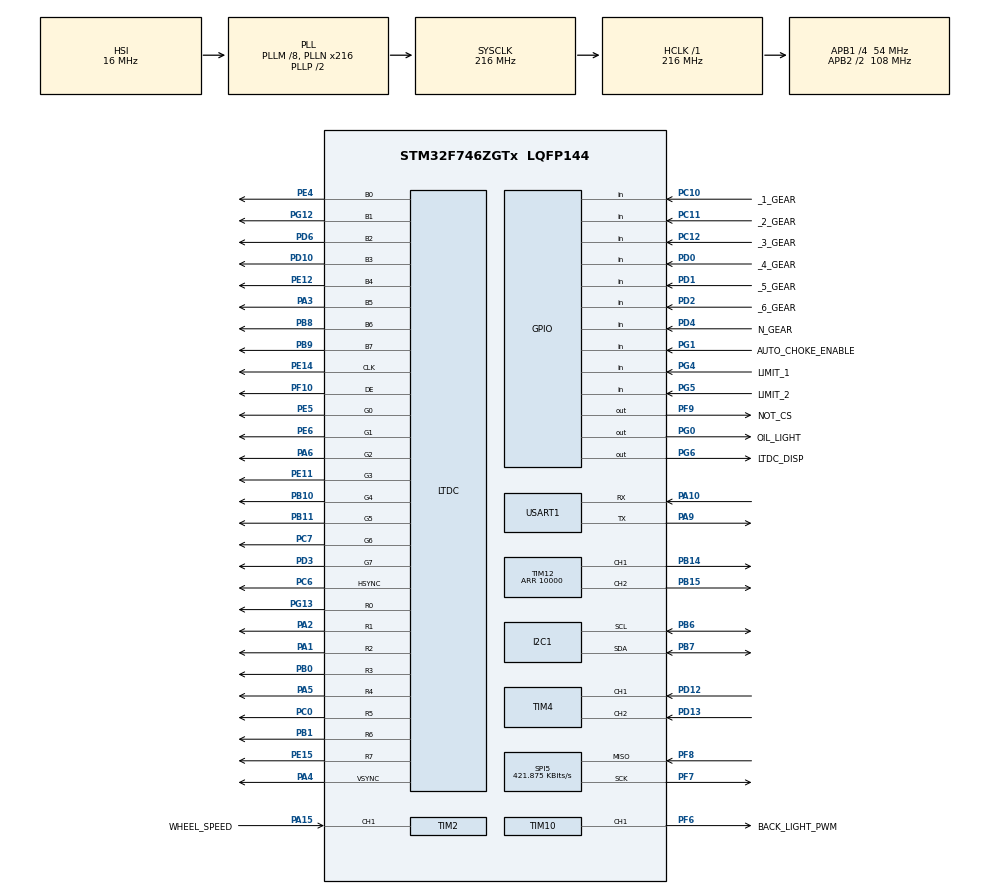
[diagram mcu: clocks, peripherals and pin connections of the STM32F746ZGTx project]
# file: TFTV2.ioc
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CORTEX_M7.ART_ACCELERATOR_ENABLE=1
CORTEX_M7.default_mode_Activation=1
DMA2D.InputColorModeForeground=DMA2D_INPUT_L8
DMA2D.Mode=DMA2D_M2M_PFC
I2C1.Timing=0x20404768
LTDC.ActiveW=800
LTDC.Alpha_L0=255
LTDC.FBStartAdress_L0=0x20000000
LTDC.HBP=8
LTDC.HFP=8
LTDC.HSync=4
LTDC.ImageHeight_L0=380
LTDC.ImageWidth_L0=600
LTDC.Layers=0
LTDC.PixelFormat_L0=LTDC_PIXEL_FORMAT_L8
LTDC.VBP=8
LTDC.VFP=8
LTDC.WindowX0_L0=100
LTDC.WindowX1_L0=700
LTDC.WindowY0_L0=50
LTDC.WindowY1_L0=380+50
Mcu.Family=STM32F7
Mcu.Name=STM32F746ZGTx
Mcu.Package=LQFP144
NVIC.DMA2D_IRQn=true\:0\:0\:false\:false\:true\:true\:true\:true
NVIC.LTDC_IRQn=true\:0\:0\:false\:false\:true\:true\:true\:true
NVIC.PriorityGroup=NVIC_PRIORITYGROUP_4
NVIC.RCC_IRQn=true\:0\:0\:false\:false\:true\:true\:false\:true
NVIC.TIM6_DAC_IRQn=true\:15\:0\:true\:false\:true\:false\:true\:true
NVIC.TimeBase=TIM6_DAC_IRQn
NVIC.TimeBaseIP=TIM6
NVIC.USART1_IRQn=true\:0\:0\:false\:false\:true\:true\:true\:true
PA1.Mode=RGB888
PA1.Signal=LTDC_R2
PA10.Mode=Asynchronous
PA10.Signal=USART1_RX
PA13.Mode=Trace_Asynchronous_SW
PA13.Signal=SYS_JTMS-SWDIO
PA14.Mode=Trace_Asynchronous_SW
PA14.Signal=SYS_JTCK-SWCLK
PA15.GPIO_Label=WHEEL_SPEED
PA15.Signal=S_TIM2_CH1_ETR
PA2.Mode=RGB888
PA2.Signal=LTDC_R1
PA3.Mode=RGB888
PA3.Signal=LTDC_B5
PA4.Mode=RGB888
PA4.Signal=LTDC_VSYNC
PA5.Mode=RGB888
PA5.Signal=LTDC_R4
PA6.Mode=RGB888
PA6.Signal=LTDC_G2
PA9.Mode=Asynchronous
PA9.Signal=USART1_TX
PB0.Mode=RGB888
PB0.Signal=LTDC_R3
PB1.Mode=RGB888
PB1.Signal=LTDC_R6
PB10.Mode=RGB888
PB10.Signal=LTDC_G4
PB11.Mode=RGB888
PB11.Signal=LTDC_G5
PB14.Signal=S_TIM12_CH1
PB15.Signal=S_TIM12_CH2
PB3.Mode=Trace_Asynchronous_SW
PB3.Signal=SYS_JTDO-SWO
PB6.Mode=I2C
PB6.Signal=I2C1_SCL
PB7.Mode=I2C
PB7.Signal=I2C1_SDA
PB8.Mode=RGB888
PB8.Signal=LTDC_B6
PB9.Mode=RGB888
PB9.Signal=LTDC_B7
PC0.Mode=RGB888
PC0.Signal=LTDC_R5
PC10.GPIO_Label=_1_GEAR
PC10.GPIO_PuPd=GPIO_PULLUP
PC10.Signal=GPIO_Input
PC11.GPIO_Label=_2_GEAR
PC11.GPIO_PuPd=GPIO_PULLUP
PC11.Signal=GPIO_Input
PC12.GPIO_Label=_3_GEAR
PC12.GPIO_PuPd=GPIO_PULLUP
PC12.Signal=GPIO_Input
PC6.Mode=RGB888
PC6.Signal=LTDC_HSYNC
PC7.Mode=RGB888
PC7.Signal=LTDC_G6
PD0.GPIO_Label=_4_GEAR
PD0.GPIO_PuPd=GPIO_PULLUP
PD0.Signal=GPIO_Input
PD1.GPIO_Label=_5_GEAR
PD1.GPIO_PuPd=GPIO_PULLUP
PD1.Signal=GPIO_Input
PD10.Mode=RGB888
PD10.Signal=LTDC_B3
PD12.Signal=S_TIM4_CH1
PD13.Signal=S_TIM4_CH2
PD2.GPIO_Label=_6_GEAR
PD2.GPIO_PuPd=GPIO_PULLUP
PD2.Signal=GPIO_Input
PD3.Mode=RGB888
PD3.Signal=LTDC_G7
PD4.GPIO_Label=N_GEAR
PD4.GPIO_PuPd=GPIO_PULLUP
PD4.Signal=GPIO_Input
PD6.Mode=RGB888
PD6.Signal=LTDC_B2
PE11.Mode=RGB888
PE11.Signal=LTDC_G3
PE12.Mode=RGB888
PE12.Signal=LTDC_B4
PE14.Mode=RGB888
PE14.Signal=LTDC_CLK
PE15.Mode=RGB888
PE15.Signal=LTDC_R7
PE4.Mode=RGB888
PE4.Signal=LTDC_B0
PE5.Mode=RGB888
PE5.Signal=LTDC_G0
PE6.Mode=RGB888
PE6.Signal=LTDC_G1
PF10.Mode=RGB888
PF10.Signal=LTDC_DE
PF6.GPIO_Label=BACK_LIGHT_PWM
PF6.Signal=S_TIM10_CH1
PF7.Mode=RX_Only_Simplex_Unidirect_Master
PF7.Signal=SPI5_SCK
PF8.Mode=RX_Only_Simplex_Unidirect_Master
PF8.Signal=SPI5_MISO
PF9.GPIO_Label=NOT_CS
PF9.Signal=GPIO_Output
PG0.GPIO_Label=OIL_LIGHT
PG0.GPIO_PuPd=GPIO_PULLDOWN
PG0.GPIO_Speed=GPIO_SPEED_FREQ_LOW
PG0.PinState=GPIO_PIN_RESET
PG0.Signal=GPIO_Output
PG1.GPIO_Label=AUTO_CHOKE_ENABLE
PG1.GPIO_PuPd=GPIO_PULLDOWN
PG1.Signal=GPIO_Input
PG12.Mode=RGB888
PG12.Signal=LTDC_B1
PG13.Mode=RGB888
PG13.Signal=LTDC_R0
PG4.GPIO_Label=LIMIT_1
PG4.GPIO_PuPd=GPIO_PULLUP
PG4.Signal=GPIO_Input
PG5.GPIO_Label=LIMIT_2
PG5.GPIO_PuPd=GPIO_PULLUP
PG5.Signal=GPIO_Input
PG6.GPIO_Label=LTDC_DISP
PG6.GPIO_PuPd=GPIO_PULLUP
PG6.PinState=GPIO_PIN_SET
PG6.Signal=GPIO_Output
PH0/OSC_IN.Mode=HSE-External-Oscillator
PH0/OSC_IN.Signal=RCC_OSC_IN
PH1/OSC_OUT.Mode=HSE-External-Oscillator
PH1/OSC_OUT.Signal=RCC_OSC_OUT
ProjectManager.HeapSize=0x200
ProjectManager.StackSize=0x400
ProjectManager.TargetToolchain=STM32CubeIDE
RCC.AHBFreq_Value=216000000
RCC.APB1CLKDivider=RCC_HCLK_DIV4
RCC.APB1Freq_Value=54000000
RCC.APB1TimFreq_Value=108000000
RCC.APB2CLKDivider=RCC_HCLK_DIV2
RCC.APB2Freq_Value=108000000
RCC.APB2TimFreq_Value=216000000
RCC.CortexFreq_Value=216000000
RCC.HCLKFreq_Value=216000000
RCC.HSE_VALUE=25000000
RCC.HSI_VALUE=16000000
RCC.LSE_VALUE=32768
RCC.PLLM=8
RCC.PLLN=216
RCC.PLLSAIN=50
RCC.SYSCLKFreq_VALUE=216000000
RCC.SYSCLKSource=RCC_SYSCLKSOURCE_PLLCLK
RCC.USBFreq_Value=216000000
RCC.VCOOutputFreq_Value=432000000
SH.S_TIM10_CH1.0=TIM10_CH1,PWM Generation1 CH1
SH.S_TIM12_CH1.0=TIM12_CH1,PWM Generation1 CH1
SH.S_TIM12_CH2.0=TIM12_CH2,PWM Generation2 CH2
SH.S_TIM2_CH1_ETR.0=TIM2_CH1,TriggerSource_TI1FP1
SH.S_TIM4_CH1.0=TIM4_CH1,Encoder_Interface
SH.S_TIM4_CH2.0=TIM4_CH2,Encoder_Interface
SPI5.BaudRatePrescaler=SPI_BAUDRATEPRESCALER_256
SPI5.CalculateBaudRate=421.875 KBits/s
SPI5.DataSize=SPI_DATASIZE_16BIT
SPI5.Direction=SPI_DIRECTION_2LINES_RXONLY
SPI5.Mode=SPI_MODE_MASTER
SPI5.VirtualType=VM_MASTER
STMicroelectronics.X-CUBE-TOUCHGFX.4.25.0.ApplicationCcGraphicsJjApplication=TouchGFXOoGenerator
STMicroelectronics.X-CUBE-TOUCHGFX.4.25.0.tgfx_display_interface=disp_ltdc
STMicroelectronics.X-CUBE-TOUCHGFX.4.25.0.tgfx_hardware_accelerator=dma_2d
STMicroelectronics.X-CUBE-TOUCHGFX.4.25.0.tgfx_pixel_format=RGBA2222\:8
STMicroelectronics.X-CUBE-TOUCHGFX.4.25.0.tgfx_vsync=vsync_ltdc
STMicroelectronics.X-CUBE-TOUCHGFX.4.25.0_IsPackSelfContextualization=true
TIM10.Channel=TIM_CHANNEL_1
TIM10.Period=2159
TIM12.Channel-PWM\ Generation1\ CH1=TIM_CHANNEL_1
TIM12.Channel-PWM\ Generation2\ CH2=TIM_CHANNEL_2
TIM12.Period=10000
TIM4.EncoderMode=TIM_ENCODERMODE_TI12
USART1.VirtualMode-Asynchronous=VM_ASYNC
VP_CRC_VS_CRC.Mode=CRC_Activate
VP_DMA2D_VS_DMA2D.Mode=DMA2D_Activate
VP_STMicroelectronics.X-CUBE-TOUCHGFX_VS_GraphicsJjApplication_4.25.0.Mode=GraphicsJjApplication
VP_SYS_VS_tim6.Mode=TIM6
VP_TIM10_VS_ClockSourceINT.Mode=Enable_Timer
VP_TIM2_VS_ControllerModeClock.Mode=Clock Mode
board=custom

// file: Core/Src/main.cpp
/* USER CODE BEGIN Header */
/**
  ******************************************************************************
  * @file           : main.cpp
  * @brief          : Main program body for GS425-Dashboard that runs tasks
                      containing FSMs.
  ******************************************************************************
  * @attention
  *
  * Copyright (c) 2025 STMicroelectronics.
  * All rights reserved.
  *
  * This software is licensed under terms that can be found in the LICENSE file
  * in the root directory of this software component.
  * If no LICENSE file comes with this software, it is provided AS-IS.
  *
  ******************************************************************************
  */
/* USER CODE END Header */
#include "main.h"

/* USER CODE BEGIN Includes */
#include <stdio.h>
#include <string.h>
#include <stdbool.h>
#include "task1.h"
#include "task2.h"
#include "app_touchgfx.h"

  TASK1 task1;   // init task 1
  TASK2 task2;   // init task 2

/* USER CODE END Includes */

CRC_HandleTypeDef hcrc;

DMA2D_HandleTypeDef hdma2d;

I2C_HandleTypeDef hi2c1;

LTDC_HandleTypeDef hltdc;

SPI_HandleTypeDef hspi5;

TIM_HandleTypeDef htim2;
TIM_HandleTypeDef htim4;
TIM_HandleTypeDef htim10;
TIM_HandleTypeDef htim12;

UART_HandleTypeDef huart1;

void SystemClock_Config(void);
static void MPU_Config(void);
static void MX_GPIO_Init(void);
static void MX_DMA2D_Init(void);
static void MX_I2C1_Init(void);
static void MX_LTDC_Init(void);
static void MX_USART1_UART_Init(void);
static void MX_CRC_Init(void);
static void MX_TIM10_Init(void);
static void MX_TIM2_Init(void);
static void MX_SPI5_Init(void);
static void MX_TIM4_Init(void);
static void MX_TIM12_Init(void);

int main(void)
{

  /* MPU Configuration--------------------------------------------------------*/
  MPU_Config();

  /* MCU Configuration--------------------------------------------------------*/

  /* Reset of all peripherals, Initializes the Flash interface and the Systick. */
  HAL_Init();

  /* Configure the system clock */
  SystemClock_Config();

  /* Initialize all configured peripherals */
  MX_GPIO_Init();
  MX_DMA2D_Init();
  MX_I2C1_Init();
  MX_LTDC_Init();
  MX_USART1_UART_Init();
  MX_CRC_Init();
  MX_TIM10_Init();
  MX_TIM2_Init();
  MX_SPI5_Init();
  MX_TIM4_Init();
  MX_TIM12_Init();
  MX_TouchGFX_Init();
  /* USER CODE BEGIN 2 */

	//Set up BackLight PWM Channel
	__HAL_TIM_SET_COMPARE(&htim10, TIM_CHANNEL_1, 500);
	HAL_TIM_PWM_Start(&htim10, TIM_CHANNEL_1);

  /* USER CODE END 2 */

  /* Infinite loop */
  /* USER CODE BEGIN WHILE */
  while (1)
  {
	  task1.run();            // task 1
	  task2.run();            // task 2
      MX_TouchGFX_Process();  // task 3

    /* USER CODE END WHILE */

  }
}

void SystemClock_Config(void)
{
  RCC_OscInitTypeDef RCC_OscInitStruct = {0};
  RCC_ClkInitTypeDef RCC_ClkInitStruct = {0};

  /** Configure the main internal regulator output voltage
  */
  __HAL_RCC_PWR_CLK_ENABLE();
  __HAL_PWR_VOLTAGESCALING_CONFIG(PWR_REGULATOR_VOLTAGE_SCALE1);

  /** Initializes the RCC Oscillators according to the specified parameters
  * in the RCC_OscInitTypeDef structure.
  */
  RCC_OscInitStruct.OscillatorType = RCC_OSCILLATORTYPE_HSI;
  RCC_OscInitStruct.HSIState = RCC_HSI_ON;
  RCC_OscInitStruct.HSICalibrationValue = RCC_HSICALIBRATION_DEFAULT;
  RCC_OscInitStruct.PLL.PLLState = RCC_PLL_ON;
  RCC_OscInitStruct.PLL.PLLSource = RCC_PLLSOURCE_HSI;
  RCC_OscInitStruct.PLL.PLLM = 8;
  RCC_OscInitStruct.PLL.PLLN = 216;
  RCC_OscInitStruct.PLL.PLLP = RCC_PLLP_DIV2;
  RCC_OscInitStruct.PLL.PLLQ = 2;
  if (HAL_RCC_OscConfig(&RCC_OscInitStruct) != HAL_OK)
  {
    Error_Handler();
  }

  /** Activate the Over-Drive mode
  */
  if (HAL_PWREx_EnableOverDrive() != HAL_OK)
  {
    Error_Handler();
  }

  /** Initializes the CPU, AHB and APB buses clocks
  */
  RCC_ClkInitStruct.ClockType = RCC_CLOCKTYPE_HCLK|RCC_CLOCKTYPE_SYSCLK
                              |RCC_CLOCKTYPE_PCLK1|RCC_CLOCKTYPE_PCLK2;
  RCC_ClkInitStruct.SYSCLKSource = RCC_SYSCLKSOURCE_PLLCLK;
  RCC_ClkInitStruct.AHBCLKDivider = RCC_SYSCLK_DIV1;
  RCC_ClkInitStruct.APB1CLKDivider = RCC_HCLK_DIV4;
  RCC_ClkInitStruct.APB2CLKDivider = RCC_HCLK_DIV2;

  if (HAL_RCC_ClockConfig(&RCC_ClkInitStruct, FLASH_LATENCY_7) != HAL_OK)
  {
    Error_Handler();
  }
}

static void MX_CRC_Init(void)
{

  hcrc.Instance = CRC;
  hcrc.Init.DefaultPolynomialUse = DEFAULT_POLYNOMIAL_ENABLE;
  hcrc.Init.DefaultInitValueUse = DEFAULT_INIT_VALUE_ENABLE;
  hcrc.Init.InputDataInversionMode = CRC_INPUTDATA_INVERSION_NONE;
  hcrc.Init.OutputDataInversionMode = CRC_OUTPUTDATA_INVERSION_DISABLE;
  hcrc.InputDataFormat = CRC_INPUTDATA_FORMAT_BYTES;
  if (HAL_CRC_Init(&hcrc) != HAL_OK)
  {
    Error_Handler();
  }

}

static void MX_DMA2D_Init(void)
{

  hdma2d.Instance = DMA2D;
  hdma2d.Init.Mode = DMA2D_M2M_PFC;
  hdma2d.Init.ColorMode = DMA2D_OUTPUT_ARGB8888;
  hdma2d.Init.OutputOffset = 0;
  hdma2d.LayerCfg[1].InputOffset = 0;
  hdma2d.LayerCfg[1].InputColorMode = DMA2D_INPUT_L8;
  hdma2d.LayerCfg[1].AlphaMode = DMA2D_NO_MODIF_ALPHA;
  hdma2d.LayerCfg[1].InputAlpha = 0;
  if (HAL_DMA2D_Init(&hdma2d) != HAL_OK)
  {
    Error_Handler();
  }
  if (HAL_DMA2D_ConfigLayer(&hdma2d, 1) != HAL_OK)
  {
    Error_Handler();
  }

}

static void MX_I2C1_Init(void)
{

  hi2c1.Instance = I2C1;
  hi2c1.Init.Timing = 0x20404768;
  hi2c1.Init.OwnAddress1 = 0;
  hi2c1.Init.AddressingMode = I2C_ADDRESSINGMODE_7BIT;
  hi2c1.Init.DualAddressMode = I2C_DUALADDRESS_DISABLE;
  hi2c1.Init.OwnAddress2 = 0;
  hi2c1.Init.OwnAddress2Masks = I2C_OA2_NOMASK;
  hi2c1.Init.GeneralCallMode = I2C_GENERALCALL_DISABLE;
  hi2c1.Init.NoStretchMode = I2C_NOSTRETCH_DISABLE;
  if (HAL_I2C_Init(&hi2c1) != HAL_OK)
  {
    Error_Handler();
  }

  /** Configure Analogue filter
  */
  if (HAL_I2CEx_ConfigAnalogFilter(&hi2c1, I2C_ANALOGFILTER_ENABLE) != HAL_OK)
  {
    Error_Handler();
  }

  /** Configure Digital filter
  */
  if (HAL_I2CEx_ConfigDigitalFilter(&hi2c1, 0) != HAL_OK)
  {
    Error_Handler();
  }

}

static void MX_LTDC_Init(void)
{

  LTDC_LayerCfgTypeDef pLayerCfg = {0};

  hltdc.Instance = LTDC;
  hltdc.Init.HSPolarity = LTDC_HSPOLARITY_AL;
  hltdc.Init.VSPolarity = LTDC_VSPOLARITY_AL;
  hltdc.Init.DEPolarity = LTDC_DEPOLARITY_AL;
  hltdc.Init.PCPolarity = LTDC_PCPOLARITY_IPC;
  hltdc.Init.HorizontalSync = 3;
  hltdc.Init.VerticalSync = 3;
  hltdc.Init.AccumulatedHBP = 11;
  hltdc.Init.AccumulatedVBP = 11;
  hltdc.Init.AccumulatedActiveW = 811;
  hltdc.Init.AccumulatedActiveH = 491;
  hltdc.Init.TotalWidth = 819;
  hltdc.Init.TotalHeigh = 499;
  hltdc.Init.Backcolor.Blue = 0;
  hltdc.Init.Backcolor.Green = 0;
  hltdc.Init.Backcolor.Red = 0;
  if (HAL_LTDC_Init(&hltdc) != HAL_OK)
  {
    Error_Handler();
  }
  pLayerCfg.WindowX0 = 100;
  pLayerCfg.WindowX1 = 700;
  pLayerCfg.WindowY0 = 50;
  pLayerCfg.WindowY1 = 380+50;
  pLayerCfg.PixelFormat = LTDC_PIXEL_FORMAT_L8;
  pLayerCfg.Alpha = 255;
  pLayerCfg.Alpha0 = 0;
  pLayerCfg.BlendingFactor1 = LTDC_BLENDING_FACTOR1_CA;
  pLayerCfg.BlendingFactor2 = LTDC_BLENDING_FACTOR2_CA;
  pLayerCfg.FBStartAdress = 0x20000000;
  pLayerCfg.ImageWidth = 600;
  pLayerCfg.ImageHeight = 380;
  pLayerCfg.Backcolor.Blue = 0;
  pLayerCfg.Backcolor.Green = 0;
  pLayerCfg.Backcolor.Red = 0;
  if (HAL_LTDC_ConfigLayer(&hltdc, &pLayerCfg, 0) != HAL_OK)
  {
    Error_Handler();
  }

}

static void MX_SPI5_Init(void)
{

  /* SPI5 parameter configuration*/
  hspi5.Instance = SPI5;
  hspi5.Init.Mode = SPI_MODE_MASTER;
  hspi5.Init.Direction = SPI_DIRECTION_2LINES_RXONLY;
  hspi5.Init.DataSize = SPI_DATASIZE_16BIT;
  hspi5.Init.CLKPolarity = SPI_POLARITY_LOW;
  hspi5.Init.CLKPhase = SPI_PHASE_1EDGE;
  hspi5.Init.NSS = SPI_NSS_SOFT;
  hspi5.Init.BaudRatePrescaler = SPI_BAUDRATEPRESCALER_256;
  hspi5.Init.FirstBit = SPI_FIRSTBIT_MSB;
  hspi5.Init.TIMode = SPI_TIMODE_DISABLE;
  hspi5.Init.CRCCalculation = SPI_CRCCALCULATION_DISABLE;
  hspi5.Init.CRCPolynomial = 7;
  hspi5.Init.CRCLength = SPI_CRC_LENGTH_DATASIZE;
  hspi5.Init.NSSPMode = SPI_NSS_PULSE_ENABLE;
  if (HAL_SPI_Init(&hspi5) != HAL_OK)
  {
    Error_Handler();
  }

}

static void MX_TIM2_Init(void)
{

  TIM_SlaveConfigTypeDef sSlaveConfig = {0};
  TIM_MasterConfigTypeDef sMasterConfig = {0};

  htim2.Instance = TIM2;
  htim2.Init.Prescaler = 0;
  htim2.Init.CounterMode = TIM_COUNTERMODE_UP;
  htim2.Init.Period = 4294967295;
  htim2.Init.ClockDivision = TIM_CLOCKDIVISION_DIV1;
  htim2.Init.AutoReloadPreload = TIM_AUTORELOAD_PRELOAD_DISABLE;
  if (HAL_TIM_Base_Init(&htim2) != HAL_OK)
  {
    Error_Handler();
  }
  sSlaveConfig.SlaveMode = TIM_SLAVEMODE_EXTERNAL1;
  sSlaveConfig.InputTrigger = TIM_TS_TI1FP1;
  sSlaveConfig.TriggerPolarity = TIM_TRIGGERPOLARITY_RISING;
  sSlaveConfig.TriggerFilter = 0;
  if (HAL_TIM_SlaveConfigSynchro(&htim2, &sSlaveConfig) != HAL_OK)
  {
    Error_Handler();
  }
  sMasterConfig.MasterOutputTrigger = TIM_TRGO_RESET;
  sMasterConfig.MasterSlaveMode = TIM_MASTERSLAVEMODE_DISABLE;
  if (HAL_TIMEx_MasterConfigSynchronization(&htim2, &sMasterConfig) != HAL_OK)
  {
    Error_Handler();
  }

}

static void MX_TIM4_Init(void)
{

  TIM_Encoder_InitTypeDef sConfig = {0};
  TIM_MasterConfigTypeDef sMasterConfig = {0};

  htim4.Instance = TIM4;
  htim4.Init.Prescaler = 0;
  htim4.Init.CounterMode = TIM_COUNTERMODE_UP;
  htim4.Init.Period = 65535;
  htim4.Init.ClockDivision = TIM_CLOCKDIVISION_DIV1;
  htim4.Init.AutoReloadPreload = TIM_AUTORELOAD_PRELOAD_DISABLE;
  sConfig.EncoderMode = TIM_ENCODERMODE_TI12;
  sConfig.IC1Polarity = TIM_ICPOLARITY_RISING;
  sConfig.IC1Selection = TIM_ICSELECTION_DIRECTTI;
  sConfig.IC1Prescaler = TIM_ICPSC_DIV1;
  sConfig.IC1Filter = 0;
  sConfig.IC2Polarity = TIM_ICPOLARITY_RISING;
  sConfig.IC2Selection = TIM_ICSELECTION_DIRECTTI;
  sConfig.IC2Prescaler = TIM_ICPSC_DIV1;
  sConfig.IC2Filter = 0;
  if (HAL_TIM_Encoder_Init(&htim4, &sConfig) != HAL_OK)
  {
    Error_Handler();
  }
  sMasterConfig.MasterOutputTrigger = TIM_TRGO_RESET;
  sMasterConfig.MasterSlaveMode = TIM_MASTERSLAVEMODE_DISABLE;
  if (HAL_TIMEx_MasterConfigSynchronization(&htim4, &sMasterConfig) != HAL_OK)
  {
    Error_Handler();
  }

}

static void MX_TIM10_Init(void)
{

  TIM_OC_InitTypeDef sConfigOC = {0};

  htim10.Instance = TIM10;
  htim10.Init.Prescaler = 0;
  htim10.Init.CounterMode = TIM_COUNTERMODE_UP;
  htim10.Init.Period = 2159;
  htim10.Init.ClockDivision = TIM_CLOCKDIVISION_DIV1;
  htim10.Init.AutoReloadPreload = TIM_AUTORELOAD_PRELOAD_DISABLE;
  if (HAL_TIM_Base_Init(&htim10) != HAL_OK)
  {
    Error_Handler();
  }
  if (HAL_TIM_PWM_Init(&htim10) != HAL_OK)
  {
    Error_Handler();
  }
  sConfigOC.OCMode = TIM_OCMODE_PWM1;
  sConfigOC.Pulse = 0;
  sConfigOC.OCPolarity = TIM_OCPOLARITY_HIGH;
  sConfigOC.OCFastMode = TIM_OCFAST_DISABLE;
  if (HAL_TIM_PWM_ConfigChannel(&htim10, &sConfigOC, TIM_CHANNEL_1) != HAL_OK)
  {
    Error_Handler();
  }
  HAL_TIM_MspPostInit(&htim10);

}

static void MX_TIM12_Init(void)
{

  TIM_OC_InitTypeDef sConfigOC = {0};

  htim12.Instance = TIM12;
  htim12.Init.Prescaler = 0;
  htim12.Init.CounterMode = TIM_COUNTERMODE_UP;
  htim12.Init.Period = 10000;
  htim12.Init.ClockDivision = TIM_CLOCKDIVISION_DIV1;
  htim12.Init.AutoReloadPreload = TIM_AUTORELOAD_PRELOAD_DISABLE;
  if (HAL_TIM_PWM_Init(&htim12) != HAL_OK)
  {
    Error_Handler();
  }
  sConfigOC.OCMode = TIM_OCMODE_PWM1;
  sConfigOC.Pulse = 0;
  sConfigOC.OCPolarity = TIM_OCPOLARITY_HIGH;
  sConfigOC.OCFastMode = TIM_OCFAST_DISABLE;
  if (HAL_TIM_PWM_ConfigChannel(&htim12, &sConfigOC, TIM_CHANNEL_1) != HAL_OK)
  {
    Error_Handler();
  }
  if (HAL_TIM_PWM_ConfigChannel(&htim12, &sConfigOC, TIM_CHANNEL_2) != HAL_OK)
  {
    Error_Handler();
  }
  HAL_TIM_MspPostInit(&htim12);

}

static void MX_USART1_UART_Init(void)
{

  huart1.Instance = USART1;
  huart1.Init.BaudRate = 115200;
  huart1.Init.WordLength = UART_WORDLENGTH_8B;
  huart1.Init.StopBits = UART_STOPBITS_1;
  huart1.Init.Parity = UART_PARITY_NONE;
  huart1.Init.Mode = UART_MODE_TX_RX;
  huart1.Init.HwFlowCtl = UART_HWCONTROL_NONE;
  huart1.Init.OverSampling = UART_OVERSAMPLING_16;
  huart1.Init.OneBitSampling = UART_ONE_BIT_SAMPLE_DISABLE;
  huart1.AdvancedInit.AdvFeatureInit = UART_ADVFEATURE_NO_INIT;
  if (HAL_UART_Init(&huart1) != HAL_OK)
  {
    Error_Handler();
  }

}

static void MX_GPIO_Init(void)
{
  GPIO_InitTypeDef GPIO_InitStruct = {0};

  /* GPIO Ports Clock Enable */
  __HAL_RCC_GPIOE_CLK_ENABLE();
  __HAL_RCC_GPIOF_CLK_ENABLE();
  __HAL_RCC_GPIOH_CLK_ENABLE();
  __HAL_RCC_GPIOC_CLK_ENABLE();
  __HAL_RCC_GPIOA_CLK_ENABLE();
  __HAL_RCC_GPIOB_CLK_ENABLE();
  __HAL_RCC_GPIOG_CLK_ENABLE();
  __HAL_RCC_GPIOD_CLK_ENABLE();

  /*Configure GPIO pin Output Level */
  HAL_GPIO_WritePin(NOT_CS_GPIO_Port, NOT_CS_Pin, GPIO_PIN_RESET);

  /*Configure GPIO pin Output Level */
  HAL_GPIO_WritePin(OIL_LIGHT_GPIO_Port, OIL_LIGHT_Pin, GPIO_PIN_RESET);

  /*Configure GPIO pin Output Level */
  HAL_GPIO_WritePin(LTDC_DISP_GPIO_Port, LTDC_DISP_Pin, GPIO_PIN_SET);

  /*Configure GPIO pin : NOT_CS_Pin */
  GPIO_InitStruct.Pin = NOT_CS_Pin;
  GPIO_InitStruct.Mode = GPIO_MODE_OUTPUT_PP;
  GPIO_InitStruct.Pull = GPIO_NOPULL;
  GPIO_InitStruct.Speed = GPIO_SPEED_FREQ_LOW;
  HAL_GPIO_Init(NOT_CS_GPIO_Port, &GPIO_InitStruct);

  /*Configure GPIO pin : OIL_LIGHT_Pin */
  GPIO_InitStruct.Pin = OIL_LIGHT_Pin;
  GPIO_InitStruct.Mode = GPIO_MODE_OUTPUT_PP;
  GPIO_InitStruct.Pull = GPIO_PULLDOWN;
  GPIO_InitStruct.Speed = GPIO_SPEED_FREQ_LOW;
  HAL_GPIO_Init(OIL_LIGHT_GPIO_Port, &GPIO_InitStruct);

  /*Configure GPIO pin : AUTO_CHOKE_ENABLE_Pin */
  GPIO_InitStruct.Pin = AUTO_CHOKE_ENABLE_Pin;
  GPIO_InitStruct.Mode = GPIO_MODE_INPUT;
  GPIO_InitStruct.Pull = GPIO_PULLDOWN;
  HAL_GPIO_Init(AUTO_CHOKE_ENABLE_GPIO_Port, &GPIO_InitStruct);

  /*Configure GPIO pins : LIMIT_1_Pin LIMIT_2_Pin */
  GPIO_InitStruct.Pin = LIMIT_1_Pin|LIMIT_2_Pin;
  GPIO_InitStruct.Mode = GPIO_MODE_INPUT;
  GPIO_InitStruct.Pull = GPIO_PULLUP;
  HAL_GPIO_Init(GPIOG, &GPIO_InitStruct);

  /*Configure GPIO pin : LTDC_DISP_Pin */
  GPIO_InitStruct.Pin = LTDC_DISP_Pin;
  GPIO_InitStruct.Mode = GPIO_MODE_OUTPUT_PP;
  GPIO_InitStruct.Pull = GPIO_PULLUP;
  GPIO_InitStruct.Speed = GPIO_SPEED_FREQ_LOW;
  HAL_GPIO_Init(LTDC_DISP_GPIO_Port, &GPIO_InitStruct);

  /*Configure GPIO pins : _1_GEAR_Pin _2_GEAR_Pin _3_GEAR_Pin */
  GPIO_InitStruct.Pin = _1_GEAR_Pin|_2_GEAR_Pin|_3_GEAR_Pin;
  GPIO_InitStruct.Mode = GPIO_MODE_INPUT;
  GPIO_InitStruct.Pull = GPIO_PULLUP;
  HAL_GPIO_Init(GPIOC, &GPIO_InitStruct);

  /*Configure GPIO pins : _4_GEAR_Pin _5_GEAR_Pin _6_GEAR_Pin N_GEAR_Pin */
  GPIO_InitStruct.Pin = _4_GEAR_Pin|_5_GEAR_Pin|_6_GEAR_Pin|N_GEAR_Pin;
  GPIO_InitStruct.Mode = GPIO_MODE_INPUT;
  GPIO_InitStruct.Pull = GPIO_PULLUP;
  HAL_GPIO_Init(GPIOD, &GPIO_InitStruct);

}

 /* MPU Configuration */

void MPU_Config(void)
{
  MPU_Region_InitTypeDef MPU_InitStruct = {0};

  /* Disables the MPU */
  HAL_MPU_Disable();

  /** Initializes and configures the Region and the memory to be protected
  */
  MPU_InitStruct.Enable = MPU_REGION_ENABLE;
  MPU_InitStruct.Number = MPU_REGION_NUMBER0;
  MPU_InitStruct.BaseAddress = 0x0;
  MPU_InitStruct.Size = MPU_REGION_SIZE_4GB;
  MPU_InitStruct.SubRegionDisable = 0x87;
  MPU_InitStruct.TypeExtField = MPU_TEX_LEVEL0;
  MPU_InitStruct.AccessPermission = MPU_REGION_NO_ACCESS;
  MPU_InitStruct.DisableExec = MPU_INSTRUCTION_ACCESS_DISABLE;
  MPU_InitStruct.IsShareable = MPU_ACCESS_SHAREABLE;
  MPU_InitStruct.IsCacheable = MPU_ACCESS_NOT_CACHEABLE;
  MPU_InitStruct.IsBufferable = MPU_ACCESS_NOT_BUFFERABLE;

  HAL_MPU_ConfigRegion(&MPU_InitStruct);
  /* Enables the MPU */
  HAL_MPU_Enable(MPU_PRIVILEGED_DEFAULT);

}

void HAL_TIM_PeriodElapsedCallback(TIM_HandleTypeDef *htim)
{
  if (htim->Instance == TIM6)
  {
    HAL_IncTick();
  }
}

void Error_Handler(void)
{
  __disable_irq();
  while (1)
  {
  }
}
